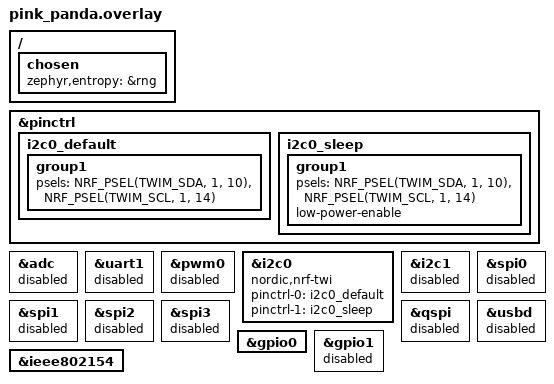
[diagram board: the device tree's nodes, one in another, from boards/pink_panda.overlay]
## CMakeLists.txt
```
list(APPEND OVERLAY_CONFIG "thread-med.conf")
list(APPEND OVERLAY_CONFIG "secret.conf")
list(APPEND OVERLAY_CONFIG "dns.conf")
list(APPEND OVERLAY_CONFIG "mqtt.conf")

cmake_minimum_required(VERSION 3.20.0)
list(APPEND BOARD_ROOT ${CMAKE_CURRENT_SOURCE_DIR})
find_package(Zephyr REQUIRED HINTS $ENV{ZEPHYR_BASE})

execute_process(COMMAND git describe
                WORKING_DIRECTORY ${CMAKE_CURRENT_SOURCE_DIR}
                OUTPUT_VARIABLE GIT_DESCRIBE
                ERROR_QUIET)
string(STRIP "${GIT_DESCRIBE}" GIT_DESCRIBE)
STRING(REGEX MATCH "[0-9]+\\.[0-9]+\\.[0-9]+"
       VERSION "${GIT_DESCRIBE}")

project(app LANGUAGES C VERSION ${VERSION})

configure_file(app_version.h.in ${CMAKE_BINARY_DIR}/app/include/app_version.h)
target_include_directories(app PRIVATE ${CMAKE_BINARY_DIR}/app/include src)

target_sources(app PRIVATE
       src/drv_i2c_master.c
       src/drv_digital_in.c
       src/drv_digital_out.c
       src/hvac.c
       src/temphum24.c
       src/openthread.c
       src/mqtt.c
       src/ha.c
       src/init.c
       src/reset.c
       src/uid.c
       src/main.c)
```

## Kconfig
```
mainmenu "Air Quality Application"

config APP_MQTT_SERVER_HOSTNAME
	string "MQTT server hostname"
	help
	  Hostname of MQTT server.

config APP_MQTT_SERVER_ADDR
	string "MQTT server address"
	help
	  MQTT server address.

config APP_MQTT_SERVER_PORT
	int "MQTT server port number"
	default 1883
	help
	  MQTT server port number.

config APP_POLL_THREAD_STACK_SIZE
	int "Poll thread stack size"
	default 2048
	help
	  Poll thread stack size.

config APP_ENABLE_SPS30
	bool "Enable particles sensor (SPS30)"
	help
	  Enable particles sensor.

source "Kconfig.zephyr"
```

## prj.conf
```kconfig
CONFIG_APP_MQTT_SERVER_HOSTNAME="home.home.arpa"
CONFIG_APP_ENABLE_SPS30=y

CONFIG_I2C=y
CONFIG_WATCHDOG=y
CONFIG_SERIAL=y
CONFIG_HEAP_MEM_POOL_SIZE=2048

CONFIG_PM_DEVICE=y

CONFIG_MAIN_STACK_SIZE=4096
CONFIG_LOG_BUFFER_SIZE=16384

CONFIG_THREAD_NAME=y
CONFIG_EVENTS=y
CONFIG_CONSOLE=y
CONFIG_UART_CONSOLE=y
CONFIG_HWINFO=y
CONFIG_NEWLIB_LIBC_FLOAT_PRINTF=y
CONFIG_JSON_LIBRARY=y
CONFIG_THREAD_ANALYZER=y
CONFIG_LOG=y
```

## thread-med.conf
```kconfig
CONFIG_FPU=y

CONFIG_SYSTEM_WORKQUEUE_STACK_SIZE=2048

CONFIG_OPENTHREAD_SLAAC=y
CONFIG_OPENTHREAD_CHANNEL=15
CONFIG_OPENTHREAD_NETWORK_NAME="home"
CONFIG_OPENTHREAD_XPANID="42:24:00:00:00:00:10:00"
CONFIG_OPENTHREAD_MTD=y

CONFIG_NETWORKING=y
CONFIG_NET_L2_OPENTHREAD=y

CONFIG_NET_TCP=y
CONFIG_NET_BUF_TX_COUNT=64
CONFIG_NET_LOG=y
```

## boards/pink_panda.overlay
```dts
/* Copyright (c) 2020 Nordic Semiconductor ASA
 *
 * SPDX-License-Identifier: LicenseRef-Nordic-5-Clause
 */

/ {
	/*
	* In some default configurations within the nRF Connect SDK,
	* e.g. on nRF52840, the chosen zephyr,entropy node is &cryptocell.
	* This devicetree overlay ensures that default is overridden wherever it
	* is set, as this application uses the RNG node for entropy exclusively.
	*/
	chosen {
		zephyr,entropy = &rng;
	};
};
&pinctrl {
	i2c0_default: i2c0_default {
		group1 {
			psels = <NRF_PSEL(TWIM_SDA, 1, 10)>,
				<NRF_PSEL(TWIM_SCL, 1, 14)>;
		};
	};

	i2c0_sleep: i2c0_sleep {
		group1 {
			psels = <NRF_PSEL(TWIM_SDA, 1, 10)>,
				<NRF_PSEL(TWIM_SCL, 1, 14)>;
			low-power-enable;
		};
	};
};
&adc {
	status = "disabled";
};
&uart1 {
	status = "disabled";
};
&pwm0 {
	status = "disabled";
};
&i2c0 {
	compatible = "nordic,nrf-twi";
	status = "okay";
	pinctrl-0 = <&i2c0_default>;
	pinctrl-1 = <&i2c0_sleep>;
	pinctrl-names = "default", "sleep";
};
&i2c1 {
	status = "disabled";
};
&spi0 {
	status = "disabled";
};
&spi1 {
	status = "disabled";
};
&spi2 {
	status = "disabled";
};
&spi3 {
	status = "disabled";
};
&qspi {
	status = "disabled";
};
&usbd {
	status = "disabled";
};
&gpio0 {
	status = "okay";
};
&gpio1 {
	status = "disabled";
};
&ieee802154 {
	status = "okay";
};
```

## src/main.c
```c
#include <zephyr/drivers/gpio.h>
#include <zephyr/drivers/watchdog.h>
#include <zephyr/kernel.h>
#include <zephyr/pm/device.h>
// There is an include missing in thread_analyzer.h
// Workaround by including it lower.
#include <zephyr/debug/thread_analyzer.h>

#include <zephyr/logging/log.h>
LOG_MODULE_REGISTER(main, LOG_LEVEL_DBG);

#include <app_version.h>
#include <stdio.h>

#include "ha.h"
#include "hvac.h"
#include "init.h"
#include "mqtt.h"
#include "openthread.h"
#include "reset.h"
#include "temphum24.h"
#include "uid.h"


#define SEDONDS_IN_BETWEEN_SENSOR_READING	10
#define NUMBER_OF_READINGS_IN_AVERAGE		(60 / SEDONDS_IN_BETWEEN_SENSOR_READING)

#define NUMBER_OF_LOOP_RUN_ANALYSIS		(5 * 60 / SEDONDS_IN_BETWEEN_SENSOR_READING)
#define NUMBER_OF_LOOP_RESET_WATCHDOG_SENSOR	(5 * 60 / SEDONDS_IN_BETWEEN_SENSOR_READING)

#define RETRY_DELAY_SECONDS			10


static struct ha_sensor watchdog_triggered_sensor = {
	.type = HA_BINARY_SENSOR_TYPE,
	.name = "Watchdog",
	.device_class = "problem",
	.retain = true,
};

static struct ha_sensor temperature_sensor = {
	.type = HA_SENSOR_TYPE,
	.name = "Temperature",
	.device_class = "temperature",
	.state_class = "measurement",
	.unit_of_measurement = "°C",
	.suggested_display_precision = 2,
};

static struct ha_sensor humidity_sensor = {
	.type = HA_SENSOR_TYPE,
	.name = "Humidity",
	.device_class = "humidity",
	.state_class = "measurement",
	.unit_of_measurement = "%",
	.suggested_display_precision = 1,
};

static struct ha_sensor co2_sensor = {
	.type = HA_SENSOR_TYPE,
	.name = "CO₂",
	.device_class = "carbon_dioxide",
	.state_class = "measurement",
	.unit_of_measurement = "ppm",
	.suggested_display_precision = 0,
};

#ifdef CONFIG_APP_ENABLE_SPS30
struct ha_sensor pm1_sensor = {
	.type = HA_SENSOR_TYPE,
	.name = "Particles (1.0 µm)",
	.device_class = "pm1",
	.state_class = "measurement",
	.unit_of_measurement = "µg/m³",
	.suggested_display_precision = 2,
};

struct ha_sensor pm25_sensor = {
	.type = HA_SENSOR_TYPE,
	.name = "Particles (2.5 µm)",
	.device_class = "pm25",
	.state_class = "measurement",
	.unit_of_measurement = "µg/m³",
	.suggested_display_precision = 2,
};

struct ha_sensor pm10_sensor = {
	.type = HA_SENSOR_TYPE,
	.name = "Particles (10 µm)",
	.device_class = "pm10",
	.state_class = "measurement",
	.unit_of_measurement = "µg/m³",
	.suggested_display_precision = 2,
};
#endif


static void register_sensor_retry(struct ha_sensor *sensor)
{
	int ret;

retry:
	ret = ha_register_sensor(sensor);
	if (ret < 0) {
		LOG_WRN("Could not register sensor, retrying");
		k_sleep(K_SECONDS(RETRY_DELAY_SECONDS));
		goto retry;
	}
}

static void send_binary_sensor_retry(struct ha_sensor *sensor)
{
	int ret;

retry:
	ret = ha_send_binary_sensor_state(sensor);
	if (ret < 0) {
		LOG_WRN("Could not send binary sensor, retrying");
		k_sleep(K_SECONDS(RETRY_DELAY_SECONDS));
		goto retry;
	}
}

static void set_online_retry(void)
{
	int ret;

retry:
	ret = ha_set_online();
	if (ret < 0) {
		LOG_WRN("Could not set online, retrying");
		k_sleep(K_SECONDS(RETRY_DELAY_SECONDS));
		goto retry;
	}
}

static int send_sensor_values(void)
{
	int ret;
	bool non_fatal_error = false;

	ret = ha_send_sensor_value(&temperature_sensor);
	if (ret < 0) {
		LOG_WRN("⚠️ could not send temperature");
		non_fatal_error = true;
	}

	ret = ha_send_sensor_value(&humidity_sensor);
	if (ret < 0) {
		LOG_WRN("⚠️ could not send humidity");
		non_fatal_error = true;
	}

	ret = ha_send_sensor_value(&co2_sensor);
	if (ret < 0) {
		LOG_WRN("⚠️ could not send CO2");
		non_fatal_error = true;
	}

#ifdef CONFIG_APP_ENABLE_SPS30
	ret = ha_send_sensor_value(&pm1_sensor);
	if (ret < 0) {
		LOG_WRN("⚠️ could not send pm1");
		non_fatal_error = true;
	}

	ret = ha_send_sensor_value(&pm25_sensor);
	if (ret < 0) {
		LOG_WRN("⚠️ could not send pm25");
		non_fatal_error = true;
	}

	ret = ha_send_sensor_value(&pm10_sensor);
	if (ret < 0) {
		LOG_WRN("⚠️ could not send pm10");
		non_fatal_error = true;
	}
#endif

	if (non_fatal_error) {
		return -1;
	}

	return 0;
}

static int start_sensor_measurements(temphum24_t *temphum24, hvac_t *hvac)
{
	int ret;

	// 1 measurement per second
	ret = temphum24_default_cfg(temphum24);
	if (ret < 0) {
		LOG_ERR("Could not start hdc302x");
		return ret;
	}
	// 1 measurement every 5 seconds
	hvac_scd40_send_cmd(hvac, HVAC_START_PERIODIC_MEASUREMENT);
#ifdef CONFIG_APP_ENABLE_SPS30
	// New readings are available every second
	hvac_sps30_start_measurement(hvac);
#endif

	return 0;
}

int main(void)
{
	int ret;
	int main_wdt_chan_id = -1, mqtt_wdt_chan_id = -1;
	uint32_t reset_cause;

	const struct device *wdt = DEVICE_DT_GET(DT_NODELABEL(wdt0));

	temphum24_t temphum24;
	hvac_t hvac;

	float temperature, humidity;
	measuremen_data_t hvac_data;
#ifdef CONFIG_APP_ENABLE_SPS30
	mass_and_num_cnt_data_t sps30_data;
#endif

	uint32_t main_loop_counter = 0;
	bool non_fatal_error = false;


	init_watchdog(wdt, &main_wdt_chan_id, &mqtt_wdt_chan_id);

	LOG_INF("\n\n🚀 MAIN START (%s) 🚀\n", APP_VERSION_FULL);

	reset_cause = show_reset_cause();
	clear_reset_cause();

	if (is_reset_cause_watchdog(reset_cause)
	    || is_reset_cause_button(reset_cause)) {
		ret = openthread_erase_persistent_info();
		if (ret < 0) {
			LOG_WRN("Could not erase openthread info");
		}
	}

	ret = openthread_my_start();
	if (ret < 0) {
		LOG_ERR("Could not start openthread");
		return ret;
	}

	ret = init_temphum24_click(&temphum24);
	if (ret < 0) {
		LOG_ERR("Could not initialize temphum24 click");
		return ret;
	}

	ret = init_hvac_click(&hvac);
	if (ret < 0) {
		LOG_ERR("Could not initialize hvac click");
		return ret;
	}

	ret = uid_init(&temphum24, &hvac);
	if (ret < 0) {
		LOG_ERR("Could not init uid module");
		return ret;
	}

#ifdef CONFIG_APP_ENABLE_SPS30
	ret = uid_fill_unique_ids(&watchdog_triggered_sensor,
				  &temperature_sensor,
				  &humidity_sensor,
				  &co2_sensor,
				  &pm1_sensor,
				  &pm25_sensor,
				  &pm10_sensor);
#else
	ret = uid_fill_unique_ids(&watchdog_triggered_sensor,
				  &temperature_sensor,
				  &humidity_sensor,
				  &co2_sensor);
#endif
	if (ret < 0) {
		LOG_ERR("Could fill unique ids");
		return ret;
	}

	LOG_INF("💤 waiting for openthread to be ready");
	openthread_wait_for_ready();

	mqtt_watchdog_init(wdt, mqtt_wdt_chan_id);
	ha_start(uid_get_device_id());

	register_sensor_retry(&watchdog_triggered_sensor);
	register_sensor_retry(&temperature_sensor);
	register_sensor_retry(&humidity_sensor);
	register_sensor_retry(&co2_sensor);
#ifdef CONFIG_APP_ENABLE_SPS30
	register_sensor_retry(&pm1_sensor);
	register_sensor_retry(&pm25_sensor);
	register_sensor_retry(&pm10_sensor);
#endif

	ret = start_sensor_measurements(&temphum24, &hvac);
	if (ret < 0) {
		LOG_ERR("Could not start sensor measurements");
		return ret;
	}

	LOG_INF("💤 waiting for all sensors to be ready");
	k_sleep(K_SECONDS(SEDONDS_IN_BETWEEN_SENSOR_READING));

	// We set the device online a little after sensor registrations
	// so HA gets time to process the sensor registrations first.
	set_online_retry();

	ha_set_binary_sensor_state(&watchdog_triggered_sensor,
				   is_reset_cause_watchdog(reset_cause));
	send_binary_sensor_retry(&watchdog_triggered_sensor);

	LOG_INF("🎉 init done 🎉");

	while (1) {
		ret = temphum24_read_temp_and_rh(&temphum24,
						 &temperature, &humidity);
		if (ret < 0) {
			LOG_WRN("Could not read temperture and humidity");
			non_fatal_error = true;
		}
		else {
			LOG_INF("HDC302x");
			LOG_INF("├── Temperature: %.2f°C", temperature);
			LOG_INF("└── Humidity: %.1f%%", humidity);

			ha_add_sensor_reading(&temperature_sensor, temperature);
			ha_add_sensor_reading(&humidity_sensor, humidity);
		}

		ret = hvac_scd40_read_measurement(&hvac, &hvac_data);
		if (ret < 0) {
			LOG_WRN("Could not read hvac module");
			non_fatal_error = true;
		}
		else {
			LOG_INF("SCD4x");
			LOG_INF("├── CO2 Concentration = %d ppm", hvac_data.co2_concent);
			LOG_INF("├── Temperature = %.2f°C", hvac_data.temperature);
			LOG_INF("└── R. Humidity = %.2f%%", hvac_data.r_humidity);

			ha_add_sensor_reading(&co2_sensor, hvac_data.co2_concent);
		}

#ifdef CONFIG_APP_ENABLE_SPS30
		ret = hvac_sps30_read_measured_data(&hvac, &sps30_data);
		if (ret < 0) {
			LOG_WRN("Could not read sps30 module");
			non_fatal_error = true;
		}
		else {
			LOG_INF("SPS30");
			LOG_INF("├── Mass concentration");
			LOG_INF("│   ├── PM 1.0 = %.2f μg/m³", sps30_data.mass_pm_1_0);
			LOG_INF("│   ├── PM 2.5 = %.2f μg/m³", sps30_data.mass_pm_2_5);
			LOG_INF("│   ├── PM 4.0 = %.2f μg/m³", sps30_data.mass_pm_4_0);
			LOG_INF("│   └── PM 10  = %.2f μg/m³", sps30_data.mass_pm_10);

			LOG_INF("├── Number Concentration");
			LOG_INF("│   ├── PM 0.5 = %.2f n/cm³", sps30_data.num_pm_0_5);
			LOG_INF("│   ├── PM 1.0 = %.2f n/cm³", sps30_data.num_pm_1_0);
			LOG_INF("│   ├── PM 2.5 = %.2f n/cm³", sps30_data.num_pm_2_5);
			LOG_INF("│   ├── PM 4.0 = %.2f n/cm³", sps30_data.num_pm_4_0);
			LOG_INF("│   └── PM 10  = %.2f n/cm³", sps30_data.num_pm_10);
			LOG_INF("└── Typical Particle Size = %.2f nm", sps30_data.typ_ptcl_size);
		
			ha_add_sensor_reading(&pm1_sensor, sps30_data.mass_pm_1_0);
			ha_add_sensor_reading(&pm25_sensor, sps30_data.mass_pm_2_5);
			ha_add_sensor_reading(&pm10_sensor, sps30_data.mass_pm_10);
		}
#endif

		if (main_loop_counter % NUMBER_OF_READINGS_IN_AVERAGE == 0) {
			non_fatal_error |= send_sensor_values();
		}

		if (main_loop_counter % NUMBER_OF_LOOP_RUN_ANALYSIS == 0) {
			thread_analyzer_print();
		}

		if (main_loop_counter >= NUMBER_OF_LOOP_RESET_WATCHDOG_SENSOR &&
		    ha_get_binary_sensor_state(&watchdog_triggered_sensor) == true) {
			ha_set_binary_sensor_state(&watchdog_triggered_sensor, false);
			send_binary_sensor_retry(&watchdog_triggered_sensor);
		}

		// Epilogue

		main_loop_counter += 1;

		// It's non-fatal but the watchdog will take action if it
		// keeps happening.
		if (!non_fatal_error) {
			LOG_INF("🦴 feed watchdog");
			wdt_feed(wdt, main_wdt_chan_id);
		}
		non_fatal_error = false;

		LOG_INF("💤 end of main loop");
		k_sleep(K_SECONDS(SEDONDS_IN_BETWEEN_SENSOR_READING));
	}

	return 0;
}
```

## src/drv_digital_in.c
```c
#include "drv_digital_in.h"


err_t digital_in_init( digital_in_t *in, pin_name_t name )
{
	in->pin = name;
	return gpio_pin_configure(in->port, in->pin, GPIO_INPUT);
}

uint8_t digital_in_read ( digital_in_t *in )
{
	return gpio_pin_get(in->port, in->pin);
}
```

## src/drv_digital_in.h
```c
#ifndef DRV_DIGITAL_IN_H_
#define DRV_DIGITAL_IN_H_

#include <zephyr/device.h>

#include "drv_name.h"

#ifdef __cplusplus
extern "C" {
#endif

// https://github.com/MikroElektronika/mikrosdk_v2/blob/076ab1c6ce8d141ecd5aedfcba20d84338c3c59b/drv/lib/include/drv_digital_in.h#L61
typedef enum
{
	DIGITAL_IN_SUCCESS = 0,	   /*!< Success. */
	DIGITAL_IN_UNSUPPORTED_PIN = (-1) /*!< Error. */
} digital_in_err_t;

typedef struct
{
	const struct device *port;
	gpio_pin_t pin;
} digital_in_t;

err_t digital_in_init ( digital_in_t *in, pin_name_t name );
uint8_t digital_in_read ( digital_in_t *in );

#ifdef __cplusplus
}
#endif

#endif /* DRV_DIGITAL_IN_H_ */
```

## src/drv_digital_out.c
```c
#include <zephyr/drivers/gpio.h>

#include "drv_digital_out.h"


err_t digital_out_init ( digital_out_t *out, pin_name_t name )
{
	out->pin = name;
	return gpio_pin_configure(out->port, out->pin, GPIO_OUTPUT_LOW);
}

err_t digital_out_high ( digital_out_t *out )
{
	return gpio_pin_set(out->port, out->pin, 1);
}

err_t digital_out_low ( digital_out_t *out )
{
	return gpio_pin_set(out->port, out->pin, 0);
}
```

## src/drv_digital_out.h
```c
#ifndef DRV_DIGITAL_OUT_H_
#define DRV_DIGITAL_OUT_H_

#include <zephyr/device.h>

#include "drv_name.h"

#ifdef __cplusplus
extern "C" {
#endif

// https://github.com/MikroElektronika/mikrosdk_v2/blob/076ab1c6ce8d141ecd5aedfcba20d84338c3c59b/drv/lib/include/drv_digital_out.h#L61
typedef enum
{
	DIGITAL_OUT_SUCCESS = 0,	   /*!< Success. */
	DIGITAL_OUT_UNSUPPORTED_PIN = (-1) /*!< Error. */
} digital_out_err_t;

typedef struct
{
	const struct device *port;
	gpio_pin_t pin;
} digital_out_t;

err_t digital_out_init ( digital_out_t *out, pin_name_t name );
err_t digital_out_high ( digital_out_t *out );
err_t digital_out_low ( digital_out_t *out );

#ifdef __cplusplus
}
#endif

#endif /* DRV_DIGITAL_OUT_H_ */
```

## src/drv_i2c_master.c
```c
#include <zephyr/drivers/i2c.h>

#include "drv_i2c_master.h"


void i2c_master_configure_default(i2c_master_config_t *config)
{
	config->scl = HAL_PIN_NC;
	config->sda = HAL_PIN_NC;
}

err_t i2c_master_open(i2c_master_t *obj, i2c_master_config_t *config)
{
	return I2C_MASTER_SUCCESS;
}

err_t i2c_master_set_speed(i2c_master_t *obj, uint32_t speed)
{
	return I2C_MASTER_SUCCESS;
}

err_t i2c_master_set_slave_address(i2c_master_t *obj, uint8_t address)
{
	obj->config.addr = address;
	return I2C_MASTER_SUCCESS;
}

err_t i2c_master_write(i2c_master_t *obj,
		       uint8_t *write_data_buf,
		       size_t len_write_data)
{
	return i2c_write(obj->dev, write_data_buf,
			 len_write_data, obj->config.addr);
}

err_t i2c_master_write_then_read(i2c_master_t *obj,
				 uint8_t *write_data_buf,
				 size_t len_write_data,
				 uint8_t *read_data_buf,
				 size_t len_read_data)
{
	return i2c_write_read(obj->dev,
			      obj->config.addr,
			      write_data_buf,
			      len_write_data,
			      read_data_buf,
			      len_read_data);
}

err_t i2c_master_read(i2c_master_t *obj,
		      uint8_t *read_data_buf,
		      size_t len_read_data)
{
	return i2c_read(obj->dev,
			read_data_buf,
			len_read_data,
			obj->config.addr);
}
```

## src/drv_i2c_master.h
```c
#ifndef DRV_I2C_MASTER_H_
#define DRV_I2C_MASTER_H_

#include <zephyr/device.h>

#include "drv_name.h"

#ifdef __cplusplus
extern "C" {
#endif

#define HAL_PIN_NC			-1
#define I2C_MASTER_SPEED_STANDARD	0

typedef struct {
	uint8_t addr;
	pin_name_t sda;
	pin_name_t scl;
	uint32_t speed;
	uint16_t timeout_pass_count;
} i2c_master_config_t;

typedef	struct {
	const struct device *dev;
	i2c_master_config_t config;
} i2c_master_t;

// https://github.com/MikroElektronika/mikrosdk_v2/blob/076ab1c6ce8d141ecd5aedfcba20d84338c3c59b/drv/lib/include/drv_i2c_master.h#L59
typedef enum {
	I2C_MASTER_SUCCESS = 0,  /*!< Success. */
	I2C_MASTER_ERROR = (-1)  /*!< Error. */
} i2c_master_err_t;


void i2c_master_configure_default(i2c_master_config_t *config);
err_t i2c_master_open(i2c_master_t *obj, i2c_master_config_t *config);
err_t i2c_master_set_speed(i2c_master_t *obj, uint32_t speed);
err_t i2c_master_set_slave_address(i2c_master_t *obj, uint8_t address);
err_t i2c_master_write(i2c_master_t *obj,
		       uint8_t *write_data_buf,
		       size_t len_write_data);
err_t i2c_master_write_then_read(i2c_master_t *obj,
				 uint8_t *write_data_buf,
				 size_t len_write_data,
				 uint8_t *read_data_buf,
				 size_t len_read_data);
err_t i2c_master_read(i2c_master_t *obj,
		      uint8_t *read_data_buf,
		      size_t len_read_data);

#ifdef __cplusplus
}
#endif

#endif /* DRV_I2C_MASTER_H_ */
```

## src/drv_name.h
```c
#ifndef DRV_NAME_H_
#define DRV_NAME_H_

#ifdef __cplusplus
extern "C" {
#endif

#include <zephyr/drivers/gpio.h>
#include <zephyr/kernel.h>


typedef	int32_t	err_t;
typedef	gpio_pin_t pin_name_t;

static inline void Delay_100ms ( void ) {
	k_sleep( K_MSEC( 1 ) );
}

static inline void Delay_1sec ( void ) {
	k_sleep( K_SECONDS( 1 ) );
}

#ifdef __cplusplus
}
#endif

#endif /* DRV_NAME_H_ */
```

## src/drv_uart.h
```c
typedef	void*	uart_t;
```

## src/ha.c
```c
#include <zephyr/logging/log.h>
LOG_MODULE_REGISTER(home_assistant, LOG_LEVEL_DBG);

#include <zephyr/data/json.h>

#include <stdio.h>
#include <stdlib.h>
#include <app_version.h>

#include "ha.h"
#include "mqtt.h"


#define JSON_CONFIG_BUFFER_SIZE		1024
#define UNIQUE_ID_BUFFER_SIZE		64

#define MQTT_BASE_PATH_FORMAT_STRING "air_quality/%s"
#define LAST_WILL_TOPIC_FORMAT_STRING MQTT_BASE_PATH_FORMAT_STRING "/available"
#define DISCOVERY_TOPIC_FORMAT_STRING	"homeassistant/%s/%s/config"
// #define DISCOVERY_TOPIC_FORMAT_STRING	"test/%s/%s/config"

#define AIR_QUALITY_DEVICE {						\
	.identifiers = device_id_hex_string,				\
	.name = "Air Quality Monitor",					\
	.sw_version = APP_VERSION_FULL,					\
	.hw_version = "rev1",						\
	.model = "Gold",						\
	.manufacturer = "François Gervais",				\
}

struct ha_device {
	const char *identifiers;
	const char *name;
	const char *sw_version;
	const char *hw_version;
	const char *model;
	const char *manufacturer;
};

struct ha_sensor_config {
	const char *base_path;
	const char *name;
	const char *unique_id;
	const char *object_id;
	const char *device_class;
	const char *state_class;
	const char *unit_of_measurement;
	int suggested_display_precision;
	const char *availability_topic;
	const char *state_topic;
	struct ha_device dev;
};


static const char *device_id_hex_string;
static char mqtt_base_path[HA_TOPIC_BUFFER_SIZE];

static char last_will_topic[HA_TOPIC_BUFFER_SIZE];
static const char *last_will_message = "offline";


static const struct json_obj_descr device_descr[] = {
	JSON_OBJ_DESCR_PRIM(struct ha_device, identifiers,	JSON_TOK_STRING),
	JSON_OBJ_DESCR_PRIM(struct ha_device, name,	 	JSON_TOK_STRING),
	JSON_OBJ_DESCR_PRIM(struct ha_device, sw_version,	JSON_TOK_STRING),
	JSON_OBJ_DESCR_PRIM(struct ha_device, hw_version,	JSON_TOK_STRING),
	JSON_OBJ_DESCR_PRIM(struct ha_device, model,	 	JSON_TOK_STRING),
	JSON_OBJ_DESCR_PRIM(struct ha_device, manufacturer, 	JSON_TOK_STRING),
};

static const struct json_obj_descr sensor_config_descr[] = {
	JSON_OBJ_DESCR_PRIM_NAMED(struct ha_sensor_config, "~", base_path,	JSON_TOK_STRING),
	JSON_OBJ_DESCR_PRIM(struct ha_sensor_config, name,			JSON_TOK_STRING),
	JSON_OBJ_DESCR_PRIM(struct ha_sensor_config, unique_id,			JSON_TOK_STRING),
	JSON_OBJ_DESCR_PRIM(struct ha_sensor_config, object_id,			JSON_TOK_STRING),
	JSON_OBJ_DESCR_PRIM(struct ha_sensor_config, device_class,		JSON_TOK_STRING),
	JSON_OBJ_DESCR_PRIM(struct ha_sensor_config, state_class,		JSON_TOK_STRING),
	JSON_OBJ_DESCR_PRIM(struct ha_sensor_config, unit_of_measurement,	JSON_TOK_STRING),
	JSON_OBJ_DESCR_PRIM(struct ha_sensor_config, suggested_display_precision, JSON_TOK_NUMBER),
	JSON_OBJ_DESCR_PRIM(struct ha_sensor_config, availability_topic,	JSON_TOK_STRING),
	JSON_OBJ_DESCR_PRIM(struct ha_sensor_config, state_topic,		JSON_TOK_STRING),
	JSON_OBJ_DESCR_OBJECT(struct ha_sensor_config, dev, device_descr),
};

static const struct json_obj_descr binary_sensor_config_descr[] = {
	JSON_OBJ_DESCR_PRIM_NAMED(struct ha_sensor_config, "~", base_path,	JSON_TOK_STRING),
	JSON_OBJ_DESCR_PRIM(struct ha_sensor_config, name,			JSON_TOK_STRING),
	JSON_OBJ_DESCR_PRIM(struct ha_sensor_config, unique_id,			JSON_TOK_STRING),
	JSON_OBJ_DESCR_PRIM(struct ha_sensor_config, object_id,			JSON_TOK_STRING),
	JSON_OBJ_DESCR_PRIM(struct ha_sensor_config, device_class,		JSON_TOK_STRING),
	JSON_OBJ_DESCR_PRIM(struct ha_sensor_config, availability_topic,	JSON_TOK_STRING),
	JSON_OBJ_DESCR_PRIM(struct ha_sensor_config, state_topic,		JSON_TOK_STRING),
	JSON_OBJ_DESCR_OBJECT(struct ha_sensor_config, dev, device_descr),
};

// <discovery_prefix>/<component>/[<node_id>/]<object_id>/config
//
// Best practice for entities with a unique_id is to set <object_id> to
// unique_id and omit the <node_id>.
// https://www.home-assistant.io/integrations/mqtt/#discovery-topic
static int ha_send_discovery(const char *sensor_type,
			     struct ha_sensor_config *conf)
{
	int ret;
	char json_config[JSON_CONFIG_BUFFER_SIZE];
	char discovery_topic[HA_TOPIC_BUFFER_SIZE];

	snprintf(discovery_topic, sizeof(discovery_topic),
		 DISCOVERY_TOPIC_FORMAT_STRING,
		 sensor_type, conf->unique_id);

	LOG_DBG("discovery topic: %s", discovery_topic);

	if (strcmp(sensor_type, "sensor") == 0) {
		ret = json_obj_encode_buf(
			sensor_config_descr, ARRAY_SIZE(sensor_config_descr),
			conf, json_config, sizeof(json_config));
		if (ret < 0) {
			LOG_ERR("Could not encode JSON (%d)", ret);
			return ret;
		}
	}
	else if (strcmp(sensor_type, "binary_sensor") == 0) {
		ret = json_obj_encode_buf(
			binary_sensor_config_descr,
			ARRAY_SIZE(binary_sensor_config_descr),
			conf, json_config, sizeof(json_config));
		if (ret < 0) {
			LOG_ERR("Could not encode JSON (%d)", ret);
			return ret;
		}
	}

	LOG_DBG("payload: %s", json_config);

	ret = mqtt_publish_to_topic(discovery_topic, json_config, true);
	if (ret < 0) {
		LOG_ERR("Count not publish to topic");
		return ret;
	}

	return 0;
}

int ha_start(const char *device_id)
{
	int ret;

	device_id_hex_string = device_id;

	ret = snprintf(mqtt_base_path, sizeof(mqtt_base_path),
		 MQTT_BASE_PATH_FORMAT_STRING, device_id_hex_string);
	if (ret < 0 && ret >= sizeof(mqtt_base_path)) {
		LOG_ERR("Could not set mqtt_base_path");
		return -ENOMEM;
	}

	ret = snprintf(last_will_topic, sizeof(last_will_topic),
		 LAST_WILL_TOPIC_FORMAT_STRING, device_id_hex_string);
	if (ret < 0 && ret >= sizeof(last_will_topic)) {
		LOG_ERR("Could not set last_will_topic");
		return -ENOMEM;
	}

	ret = mqtt_init(device_id_hex_string, last_will_topic, last_will_message);
	if (ret < 0) {
		LOG_ERR("could initialize MQTT");
		return ret;
	}

	return 0;
}

int ha_set_online()
{
	int ret;

	ret = mqtt_publish_to_topic(last_will_topic, "online", true);
	if (ret < 0) {
		LOG_ERR("Count not publish to topic");
		return ret;
	}

	return 0;
}

// `object_id` = `unique id`
//
// `object_id` is set to `unique id` in order to maintain full `name` flexibility
// as by default, the `entity_id` is generated from the `name` if defined and
// `entity_id` has strict character requirements.
//
// Setting the `object_id` allows HA to use it instead of the name to
// generate the `entity_id` thus allowing name to use characters unallowed
// in an `entity_id`.
//
// https://github.com/home-assistant/core/issues/4628#:~:text=Description%20of%20problem%3A%20In%20case%20device%20has%20no%20English%20characters%20in%20the%20name%20HA%20will%20generate%20an%20empty%20entity_id%20and%20it%20will%20not%20be%20possible%20to%20access%20the%20device%20from%20HA.
// 
// object_id: Used instead of name for automatic generation of entity_id
//   https://www.home-assistant.io/integrations/sensor.mqtt/#object_id
//
// Best practice for entities with a unique_id is to set <object_id> to unique_id
//   https://www.home-assistant.io/integrations/mqtt/#discovery-messages
//
// MQTT sensor example:
// https://community.home-assistant.io/t/unique-id-with-mqtt-sensor-not-working/564315/8
//
// Other usefull links:
// https://community.home-assistant.io/t/unique-id-and-object-id-are-being-ignored-in-my-mqtt-sensor/397368/14
// https://community.home-assistant.io/t/wth-are-there-unique-id-and-entity-id/467623/9
int ha_register_sensor(struct ha_sensor *sensor)
{
	int ret;
	char brief_state_topic[HA_TOPIC_BUFFER_SIZE];
	struct ha_sensor_config ha_sensor_config = {
		.base_path = mqtt_base_path,
		.name = sensor->name,
		.unique_id = sensor->unique_id,
		.object_id = sensor->unique_id,
		.device_class = sensor->device_class,
		.state_class = sensor->state_class,
		.unit_of_measurement = sensor->unit_of_measurement,
		.suggested_display_precision = sensor->suggested_display_precision,
		.availability_topic = "~/available",
		.state_topic = brief_state_topic,
		.dev = AIR_QUALITY_DEVICE,
	};

	LOG_INF("📝 registering sensor: %s", sensor->unique_id);

	ret = snprintf(brief_state_topic, sizeof(brief_state_topic),
		       "~/%s/%s/state",
		       sensor->type, sensor->unique_id);
	if (ret < 0 && ret >= sizeof(brief_state_topic)) {
		LOG_ERR("Could not set brief_state_topic");
		return -ENOMEM;
	}

	ret = snprintf(sensor->full_state_topic, sizeof(sensor->full_state_topic),
		 "%s%s",
		 mqtt_base_path,
		 brief_state_topic + 1);
	if (ret < 0 && ret >= sizeof(brief_state_topic)) {
		LOG_ERR("Could not set full_state_topic");
		return -ENOMEM;
	}

	LOG_INF("📖 send discovery");
	ret = ha_send_discovery(sensor->type, &ha_sensor_config);
	if (ret < 0) {
		LOG_ERR("Could not send discovery");
		return ret;
	}

	return 0;
}

int ha_add_sensor_reading(struct ha_sensor *sensor, double value)
{
	sensor->total_value += value;
	sensor->number_of_values += 1;

	return 0;
}

int ha_set_binary_sensor_state(struct ha_sensor *sensor, bool state)
{
	sensor->binary_state = state;

	return 0;
}

bool ha_get_binary_sensor_state(struct ha_sensor *sensor)
{
	return sensor->binary_state;
}

int ha_send_sensor_value(struct ha_sensor *sensor)
{
	int ret;
	char value_string[16];

	if (sensor->number_of_values == 0) {
		goto out;
	}

	ret = snprintf(value_string, sizeof(value_string),
		       "%g",
		       sensor->total_value / sensor->number_of_values);
	if (ret < 0 && ret >= sizeof(value_string)) {
		LOG_ERR("Could not set value_string");
		return -ENOMEM;
	}

	ret = mqtt_publish_to_topic(sensor->full_state_topic,
		value_string, sensor->retain);
	if (ret < 0) {
		LOG_ERR("Count not publish to topic");
		return ret;
	}

	sensor->total_value = 0;
	sensor->number_of_values = 0;

out:
	return 0;
}

int ha_send_binary_sensor_state(struct ha_sensor *sensor)
{
	int ret;

	ret = mqtt_publish_to_topic(sensor->full_state_topic,
		sensor->binary_state ? "ON" : "OFF", sensor->retain);
	if (ret < 0) {
		LOG_ERR("Count not publish to topic");
		return ret;
	}

	return 0;
}
```

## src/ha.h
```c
#ifndef HA_H_
#define HA_H_

#include "uid.h"

#define HA_TOPIC_BUFFER_SIZE		128

#define HA_SENSOR_TYPE				"sensor"
#define HA_BINARY_SENSOR_TYPE		"binary_sensor"

struct ha_sensor {
	// Set by user
	const char *type;
	const char *name;
	char unique_id[UID_UNIQUE_ID_STRING_SIZE];
	const char *device_class;
	const char *state_class;
	const char *unit_of_measurement;
	int suggested_display_precision;

	// Internal use
	double total_value;
	int number_of_values;
	bool binary_state;

	char full_state_topic[HA_TOPIC_BUFFER_SIZE];
};

int ha_start(const char *device_id);
int ha_set_online();
int ha_init_sensor(struct ha_sensor *);
int ha_init_binary_sensor(struct ha_sensor *);
int ha_register_sensor(struct ha_sensor *);
int ha_add_sensor_reading(struct ha_sensor *, double value);
int ha_set_binary_sensor_state(struct ha_sensor *, bool state);
bool ha_get_binary_sensor_state(struct ha_sensor *);
int ha_send_sensor_value(struct ha_sensor *);
int ha_send_binary_sensor_state(struct ha_sensor *);

#endif /* HA_H_ */
```

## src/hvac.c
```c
/****************************************************************************
** Copyright (C) 2020 MikroElektronika d.o.o.
** Contact: https://www.mikroe.com/contact
**
** Permission is hereby granted, free of charge, to any person obtaining a copy
** of this software and associated documentation files (the "Software"), to deal
** in the Software without restriction, including without limitation the rights
** to use, copy, modify, merge, publish, distribute, sublicense, and/or sell
** copies of the Software, and to permit persons to whom the Software is
** furnished to do so, subject to the following conditions:
** The above copyright notice and this permission notice shall be
** included in all copies or substantial portions of the Software.
**
** THE SOFTWARE IS PROVIDED "AS IS", WITHOUT WARRANTY OF ANY KIND,
** EXPRESS OR IMPLIED, INCLUDING BUT NOT LIMITED TO THE WARRANTIES
** OF MERCHANTABILITY, FITNESS FOR A PARTICULAR PURPOSE AND NONINFRINGEMENT.
** IN NO EVENT SHALL THE AUTHORS OR COPYRIGHT HOLDERS BE LIABLE FOR ANY CLAIM,
** DAMAGES OR OTHER LIABILITY, WHETHER IN AN ACTION OF CONTRACT, TORT
** OR OTHERWISE, ARISING FROM, OUT OF OR IN CONNECTION WITH THE SOFTWARE OR THE
**  USE OR OTHER DEALINGS IN THE SOFTWARE.
****************************************************************************/

/*!
 * @file hvac.c
 * @brief HVAC Click Driver.
 */

#include "hvac.h"

// -------------------------------------------- PRIVATE FUNCTION DECLARATIONS 

/**
 * @brief Calc CRC function.
 *
 * @details Function given an array and a number of bytes, 
 * this calculate CRC8 for those bytes.
 *
 * @note CRC is only calc'd on the data portion ( two bytes )
 * of the four bytes being sent.
 */
uint8_t dev_calc_crc ( uint8_t *data_data );

/**
 * @brief Calc Serial CRC function.
 *
 * @details Function given an array and a number of bytes,
 * this calculate CRC8 for those bytes.
 *
 * @note CRC is only calc'd on the data portion ( two bytes )
 * of the four bytes being sent.
 */
uint8_t dev_calc_uart_crc ( uint8_t *data_data, uint8_t len );

/**
 * @brief Calculate concentration function.
 *
 * @details Function calculate concentration.
 */
uint32_t dev_calc_concent ( hvac_t *ctx, uint8_t buf_num, uint8_t *tmp_buf );

/**
 * @brief IEEE754 floating point converter.
 *
 * @details Function convert 32-bit value to float.
 */
float dev_ieee_754_floating_point_convert ( uint32_t fp_data );

// --------------------------------------------------------- PUBLIC FUNCTIONS 


void hvac_cfg_setup ( hvac_cfg_t *cfg ) 
{
    // Communication gpio pins
    cfg->scl  = HAL_PIN_NC;
    cfg->sda  = HAL_PIN_NC;

    cfg->i2c_speed   = I2C_MASTER_SPEED_STANDARD;
    cfg->i2c_address = HVAC_SCD40_SLAVE_ADDR;
}


err_t hvac_init ( hvac_t *ctx, hvac_cfg_t *cfg ) 
{
    i2c_master_config_t i2c_cfg;

    i2c_master_configure_default( &i2c_cfg );

    i2c_cfg.scl = cfg->scl;
    i2c_cfg.sda = cfg->sda;

    ctx->slave_address = cfg->i2c_address;

    if ( I2C_MASTER_ERROR == i2c_master_open( &ctx->i2c, &i2c_cfg ) ) 
    {
        return I2C_MASTER_ERROR;
    }

    if ( I2C_MASTER_ERROR == i2c_master_set_slave_address( &ctx->i2c, ctx->slave_address ) ) 
    {
        return I2C_MASTER_ERROR;
    }

    if ( I2C_MASTER_ERROR == i2c_master_set_speed( &ctx->i2c, cfg->i2c_speed ) ) 
    {
        return I2C_MASTER_ERROR;
    }
    return I2C_MASTER_SUCCESS;
}

err_t hvac_generic_write ( hvac_t *ctx, uint8_t reg, uint8_t *tx_buf, uint8_t tx_len ) 
{
    uint8_t data_buf[ 257 ] = { 0 };

    data_buf[ 0 ] = reg;

    for ( uint8_t cnt = 1; cnt <= tx_len; cnt++ )
    {
        data_buf[ cnt ] = tx_buf[ cnt - 1 ];
    }

    return i2c_master_write( &ctx->i2c, data_buf, tx_len + 1 );
}

err_t hvac_generic_read ( hvac_t *ctx, uint8_t reg, uint8_t *rx_buf, uint8_t rx_len ) 
{
    return i2c_master_write_then_read( &ctx->i2c, &reg, 1, rx_buf, rx_len );
}

err_t hvac_scd40_write_data ( hvac_t *ctx, uint16_t reg, uint16_t tx_data )
{
    uint8_t temp[ 2 ];
    uint8_t tx_buf[ 5 ];
    

    tx_buf[ 0 ] = ( uint8_t ) ( reg >> 8 );
    tx_buf[ 1 ] = ( uint8_t ) reg;

    tx_buf[ 2 ] = ( uint8_t ) ( tx_data >> 8 );
    tx_buf[ 3 ] = ( uint8_t ) tx_data;

    temp[ 0 ] = tx_buf[ 2 ];
    temp[ 1 ] = tx_buf[ 3 ];

    tx_buf[ 4 ] = dev_calc_crc( &temp[ 0 ] );

    err_t error_flag = i2c_master_write( &ctx->i2c, tx_buf, 5 );

    return error_flag;
}

err_t hvac_scd40_read_data ( hvac_t *ctx, uint16_t reg, uint16_t *rx_data )
{
    uint8_t tx_buf[ 2 ];
    uint8_t rx_buf[ 3 ];
    uint16_t result;

    tx_buf[ 0 ] = ( uint8_t ) ( reg >> 8 );
    tx_buf[ 1 ] = ( uint8_t ) reg;

    err_t error_flag = i2c_master_write_then_read( &ctx->i2c, tx_buf, 2, rx_buf, 3 );
    
    result = rx_buf[ 0 ];
    result <<= 8;
    result |= rx_buf[ 1 ];

    if ( rx_buf[ 2 ] != dev_calc_crc( &rx_buf[ 0 ] ) )
    {
        error_flag = HVAC_ERROR;
    }

    *rx_data = result;

    return error_flag;
}

void hvac_scd40_send_cmd ( hvac_t *ctx, uint16_t cmd )
{
    uint8_t tx_buf[ 2 ];

    tx_buf[ 0 ] = ( uint8_t ) ( cmd >> 8 );
    tx_buf[ 1 ] = ( uint8_t ) cmd;

    i2c_master_write ( &ctx->i2c, tx_buf, 2 );
}

err_t hvac_scd40_read_measurement ( hvac_t *ctx, measuremen_data_t *read_data )
{
    uint8_t tx_buf[ 2 ];
    uint8_t rx_buf[ 15 ];
    uint16_t tmp;
    float f_temp;
    err_t error_flag;

    tx_buf[ 0 ] = ( uint8_t ) ( HVAC_READ_MEASUREMENT >> 8 );
    tx_buf[ 1 ] = ( uint8_t ) HVAC_READ_MEASUREMENT;

    error_flag = i2c_master_write_then_read( &ctx->i2c, tx_buf, 2, rx_buf, 15 );
    if ( error_flag < 0 )
    {
        return HVAC_ERROR;
    }

    tmp = rx_buf[ 0 ];
    tmp <<= 8;
    tmp |= rx_buf[ 1 ];

    read_data->co2_concent = tmp;
    
    tmp = rx_buf[ 3 ];
    tmp <<= 8;
    tmp |= rx_buf[ 4 ];
    
    f_temp = ( ( ( float ) tmp ) * 175.0 ) / 65535.0;
    f_temp -= 45.0;
    
    read_data->temperature = f_temp;
    
    tmp = rx_buf[ 6 ];
    tmp <<= 8;
    tmp |= rx_buf[ 7 ];
    
    f_temp = ( ( ( float ) tmp ) * 100.0 ) / 65535.0;
    
    read_data->r_humidity = f_temp;
    
    tmp = rx_buf[ 9 ];
    tmp <<= 8;
    tmp |= rx_buf[ 10 ];

    read_data->asc_update_count = tmp;
    
    tmp = rx_buf[ 12 ];
    tmp <<= 8;
    tmp |= rx_buf[ 13 ];

    read_data->asc_last_correction = tmp;

    return HVAC_OK;
}

err_t hvac_scd40_get_serial_number ( hvac_t *ctx, uint16_t *serial_number )
{
    uint8_t tx_buf[ 3 ];
    uint8_t rx_buf[ 9 ];
    uint16_t tmp;
    err_t error_flag;

    tx_buf[ 0 ] = ( uint8_t ) ( HVAC_GET_SERIAL_NUMBER >> 8 );
    tx_buf[ 1 ] = ( uint8_t ) HVAC_GET_SERIAL_NUMBER;
    
    error_flag = i2c_master_write_then_read( &ctx->i2c, tx_buf, 2, rx_buf, 9 );
    if ( error_flag < 0 )
    {
        return HVAC_ERROR;
    }

    tmp = rx_buf[ 0 ];
    tmp <<= 8;
    tmp |= rx_buf[ 1 ];

    serial_number[ 0 ] = tmp;

    tmp = rx_buf[ 3 ];
    tmp <<= 8;
    tmp |= rx_buf[ 4 ];

    serial_number[ 1 ] = tmp;

    tmp = rx_buf[ 6 ];
    tmp <<= 8;
    tmp |= rx_buf[ 7 ];

    serial_number[ 2 ] = tmp;

    return HVAC_OK;
}

void hvac_scd40_get_feature_set_version ( hvac_t *ctx, feature_data_t *f_data )
{
    uint8_t tx_buf[ 3 ];
    uint8_t rx_buf[ 3 ];

    tx_buf[ 0 ] = ( uint8_t ) ( HVAC_GET_SERIAL_NUMBER >> 8 );
    tx_buf[ 1 ] = ( uint8_t ) HVAC_GET_SERIAL_NUMBER;

    i2c_master_write( &ctx->i2c, tx_buf, 2 );
    i2c_master_read( &ctx->i2c, rx_buf, 3 );
    
    f_data->product_type          = rx_buf[ 0 ] >> 4;
    f_data->platform_type         = rx_buf[ 0 ] >> 1;
    f_data->product_major_version = rx_buf[ 1 ] >> 5;
    f_data->product_minor_version = rx_buf[ 1 ];
}

void hvac_scd40_set_temperature_offset ( hvac_t *ctx, float temp_offset )
{
    uint16_t temp_val;

    temp_val = ( uint16_t ) ( temp_offset * 374.0 );
    
    hvac_scd40_write_data( ctx, HVAC_SET_TEMPERATURE_OFFSET, temp_val );
}

float hvac_scd40_get_temperature_offset ( hvac_t *ctx )
{
    uint16_t rx_buf[ 1 ];
    float temp_offset;

    hvac_scd40_read_data( ctx, HVAC_GET_TEMPERATURE_OFFSET, rx_buf );
    
    temp_offset = ( float ) rx_buf[ 0 ];
    temp_offset *= 175.0;
    temp_offset /= 65535.0;
    
    return temp_offset;
}

err_t hvac_sps30_i2c_write_data ( hvac_t *ctx, uint16_t reg, uint16_t tx_data )
{
    uint8_t temp[ 2 ];
    uint8_t tx_buf[ 5 ];

    tx_buf[ 0 ] = ( uint8_t ) ( reg >> 8 );
    tx_buf[ 1 ] = ( uint8_t ) reg;

    tx_buf[ 2 ] = ( uint8_t ) ( tx_data >> 8 );
    tx_buf[ 3 ] = ( uint8_t ) tx_data;

    temp[ 0 ] = tx_buf[ 2 ];
    temp[ 1 ] = tx_buf[ 3 ];

    tx_buf[ 4 ] = dev_calc_crc( &temp[ 0 ] );
    
    i2c_master_set_slave_address( &ctx->i2c, HVAC_SPS30_SLAVE_ADDR );

    err_t error_flag = i2c_master_write( &ctx->i2c, tx_buf, 5 );
    
    i2c_master_set_slave_address( &ctx->i2c, HVAC_SCD40_SLAVE_ADDR );

    return error_flag;
}

err_t hvac_sps30_i2c_read_data_as_bytes ( hvac_t *ctx, uint16_t reg, uint8_t *rx_data, size_t num_words )
{
    size_t read_len = num_words * ( HVAC_SPS30_WORD_SIZE + HVAC_SPS30_CRC8_LEN );
    size_t i, j;
    uint8_t tx_buf[ 2 ];
    uint8_t rx_buf[ read_len ];
    err_t error_flag;

    tx_buf[ 0 ] = ( uint8_t ) ( reg >> 8 );
    tx_buf[ 1 ] = ( uint8_t ) reg;

    i2c_master_set_slave_address( &ctx->i2c, HVAC_SPS30_SLAVE_ADDR );

    error_flag = i2c_master_write( &ctx->i2c, tx_buf, 2 );
    if (error_flag < 0)
    {
        return error_flag;
    }

    error_flag = i2c_master_read( &ctx->i2c, rx_buf, read_len );
    if (error_flag < 0)
    {
        return error_flag;
    }

    i2c_master_set_slave_address( &ctx->i2c, HVAC_SCD40_SLAVE_ADDR );

    /* check the CRC for each word */
    for ( i = 0, j = 0; i < read_len; i += HVAC_SPS30_WORD_SIZE + HVAC_SPS30_CRC8_LEN )
    {
        if ( rx_buf[ i + HVAC_SPS30_WORD_SIZE ] != dev_calc_crc( &rx_buf[ i ] ) )
        {
            return HVAC_ERROR;
        }

        rx_data[j++] = rx_buf[ i ];
        rx_data[j++] = rx_buf[ i + 1 ];
    }

    return HVAC_OK;
}

err_t hvac_sps30_i2c_read_data ( hvac_t *ctx, uint16_t reg, uint16_t *rx_data )
{
    err_t error_flag;

    error_flag = hvac_sps30_i2c_read_data_as_bytes( ctx, reg,
                        ( uint8_t * ) rx_data, sizeof( *rx_data ) );
    if (error_flag < 0)
    {
        return error_flag;
    }

    const uint8_t * word_bytes = ( uint8_t * ) rx_data;
    *rx_data = ( ( uint16_t ) word_bytes[0] << 8 ) | word_bytes[1];

    return HVAC_OK;
}

void hvac_sps30_start_measurement ( hvac_t *ctx )
{
    hvac_sps30_i2c_write_data( ctx, HVAC_SPS30_I2C_START_MEASUREMENT, 
                                    HVAC_SPS30_I2C_READ_MEASURED_VALUE );
}

void hvac_sps30_stop_measurement ( hvac_t *ctx )
{

    hvac_sps30_i2c_write_data( ctx, HVAC_SPS30_I2C_STOP_MEASUREMENT, 
                                    HVAC_SPS30_I2C_STOP_MEASUREMENT_DUMMY );
}

void hvac_sps30_device_reset ( hvac_t *ctx )
{

    hvac_sps30_i2c_write_data( ctx, HVAC_SPS30_I2C_RESET, HVAC_SPS30_I2C_STOP_MEASUREMENT_DUMMY );
}

uint8_t hvac_sps30_get_ready_flag ( hvac_t *ctx )
{
    uint16_t rx_buf;
    uint8_t ready_flag;
    
    hvac_sps30_i2c_read_data( ctx, HVAC_SPS30_I2C_READ_DATA_RDY_FLAG, &rx_buf );
    
    ready_flag = ( uint8_t ) rx_buf;
    ready_flag &= 0x01;
    return ready_flag;
}

static float hvac_sps30_bytes_to_float (  const uint8_t* bytes ) {
    uint32_t u32_value;

    u32_value = (uint32_t)bytes[0] << 24 | (uint32_t)bytes[1] << 16 |
                    (uint32_t)bytes[2] << 8 | (uint32_t)bytes[3];

    return *( float * ) &u32_value;
}

err_t hvac_sps30_read_measured_data ( hvac_t *ctx, mass_and_num_cnt_data_t *m_n_c_data )
{
    err_t error_flag;
    uint8_t data[10][4];

    error_flag = hvac_sps30_i2c_read_data_as_bytes(
                    ctx, HVAC_SPS30_I2C_READ_MEASURED_VALUE,
                    &data[0][0], HVAC_SPS30_NUM_WORDS(data));
    if ( error_flag )
    {
        return error_flag;
    }

    m_n_c_data->mass_pm_1_0 = hvac_sps30_bytes_to_float( data[0] );
    m_n_c_data->mass_pm_2_5 = hvac_sps30_bytes_to_float( data[1] );
    m_n_c_data->mass_pm_4_0 = hvac_sps30_bytes_to_float( data[2] );
    m_n_c_data->mass_pm_10 = hvac_sps30_bytes_to_float( data[3] );
    m_n_c_data->num_pm_0_5 = hvac_sps30_bytes_to_float( data[4] );
    m_n_c_data->num_pm_1_0 = hvac_sps30_bytes_to_float( data[5] );
    m_n_c_data->num_pm_2_5 = hvac_sps30_bytes_to_float( data[6] );
    m_n_c_data->num_pm_4_0 = hvac_sps30_bytes_to_float( data[7] );
    m_n_c_data->num_pm_10 = hvac_sps30_bytes_to_float( data[8] );
    m_n_c_data->typ_ptcl_size = hvac_sps30_bytes_to_float( data[9] );

    return HVAC_OK;
}

err_t hvac_sps30_get_serial_number ( hvac_t *ctx, char *serial_number,
                                    size_t serial_buffer_size )
{
    err_t error_flag;

    if ( serial_buffer_size < HVAC_SPS30_MAX_SERIAL_LEN )
    {
        return HVAC_ERROR;
    }

    error_flag = hvac_sps30_i2c_read_data_as_bytes(
                    ctx, HVAC_SPS30_I2C_READ_SERIAL_NUMBER,
                    ( uint8_t * ) serial_number,
                    serial_buffer_size / HVAC_SPS30_WORD_SIZE);
    if ( error_flag )
    {
        return error_flag;
    }

    return HVAC_OK;
}

// --------------------------------------------- PRIVATE FUNCTION DEFINITIONS 

uint8_t dev_calc_crc ( uint8_t *data_data )
{
    uint8_t crc = 0xFF;
    uint8_t bit_bit;
    uint8_t n_cnt;
 
    for ( n_cnt = 0; n_cnt < 2; n_cnt++ )
    {
        crc ^= data_data[ n_cnt ];
         
        for ( bit_bit = 8; bit_bit > 0; --bit_bit )
        {
             if ( crc & 0x80 )
             {
                 crc = ( crc << 1 ) ^ 0x31u;
             }
             else
             {
                 crc = ( crc << 1 );
             }
        }
    }
 
    return crc;
}

uint8_t dev_calc_uart_crc ( uint8_t *data_data, uint8_t len )
{
    uint8_t crc = 0xFF;
    uint8_t bit_bit;
    uint8_t n_cnt;

    for ( n_cnt = 0; n_cnt < len; n_cnt++ )
    {
        crc ^= data_data[ n_cnt ];

        for ( bit_bit = 8; bit_bit > 0; --bit_bit )
        {
             if ( crc & 0x80 )
             {
                 crc = ( crc << 1 ) ^ 0x31u;
             }
             else
             {
                 crc = ( crc << 1 );
             }
        }
    }

    return crc;
}

// ------------------------------------------------------------------------- END
```
